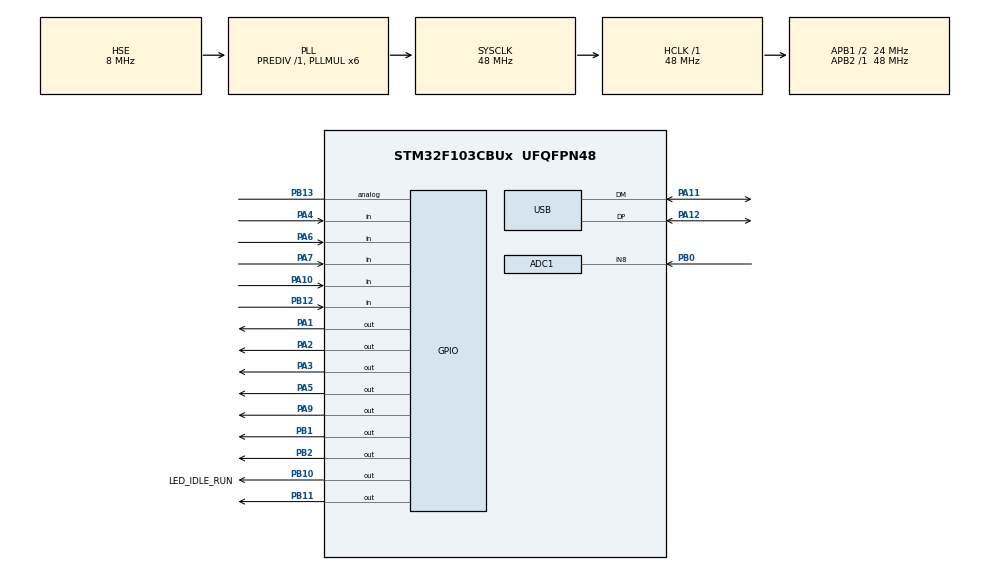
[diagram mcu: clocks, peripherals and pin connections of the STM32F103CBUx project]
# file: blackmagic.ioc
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ADC1.Channel-0\#ChannelRegularConversion=ADC_CHANNEL_8
ADC1.NbrOfConversionFlag=1
ADC1.Rank-0\#ChannelRegularConversion=1
ADC1.SamplingTime-0\#ChannelRegularConversion=ADC_SAMPLETIME_1CYCLE_5
ADC1.master=1
Mcu.Family=STM32F1
Mcu.Name=STM32F103CBUx
Mcu.Package=UFQFPN48
NVIC.PriorityGroup=NVIC_PRIORITYGROUP_4
NVIC.USB_LP_CAN1_RX0_IRQn=true\:0\:0\:false\:false\:true\:false\:true
PA1.Signal=GPIO_Output
PA10.Signal=GPIO_Input
PA11.Mode=Device
PA11.Signal=USB_DM
PA12.Mode=Device
PA12.Signal=USB_DP
PA13.Mode=Serial_Wire
PA13.Signal=SYS_JTMS-SWDIO
PA14.Mode=Serial_Wire
PA14.Signal=SYS_JTCK-SWCLK
PA2.Signal=GPIO_Output
PA3.Signal=GPIO_Output
PA4.Signal=GPIO_Input
PA5.Signal=GPIO_Output
PA6.Signal=GPIO_Input
PA7.Signal=GPIO_Input
PA9.Signal=GPIO_Output
PB0.Signal=ADCx_IN8
PB1.Signal=GPIO_Output
PB10.GPIO_Label=LED_IDLE_RUN
PB10.Signal=GPIO_Output
PB11.Signal=GPIO_Output
PB12.Signal=GPIO_Input
PB13.Signal=GPIO_Analog
PB2.Signal=GPIO_Output
PB3.Signal=SYS_JTDO-TRACESWO
PD0-OSC_IN.Mode=HSE-External-Oscillator
PD0-OSC_IN.Signal=RCC_OSC_IN
PD1-OSC_OUT.Mode=HSE-External-Oscillator
PD1-OSC_OUT.Signal=RCC_OSC_OUT
ProjectManager.HeapSize=0x200
ProjectManager.StackSize=0x400
ProjectManager.TargetToolchain=STM32CubeIDE
RCC.ADCPresc=RCC_ADCPCLK2_DIV4
RCC.AHBFreq_Value=48000000
RCC.APB1CLKDivider=RCC_HCLK_DIV2
RCC.APB1Freq_Value=24000000
RCC.APB1TimFreq_Value=48000000
RCC.APB2Freq_Value=48000000
RCC.APB2TimFreq_Value=48000000
RCC.HCLKFreq_Value=48000000
RCC.PLLMUL=RCC_PLL_MUL6
RCC.SYSCLKFreq_VALUE=48000000
RCC.SYSCLKSource=RCC_SYSCLKSOURCE_PLLCLK
RCC.USBFreq_Value=48000000
SH.ADCx_IN8.0=ADC1_IN8,IN8
USB_DEVICE.CLASS_NAME_FS=CDC
USB_DEVICE.VirtualMode=Cdc
USB_DEVICE.VirtualModeFS=Cdc_FS
VP_USB_DEVICE_VS_USB_DEVICE_CDC_FS.Mode=CDC_FS
board=custom

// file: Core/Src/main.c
/* USER CODE BEGIN Header */
/**
  ******************************************************************************
  * @file           : main.c
  * @brief          : Main program body
  ******************************************************************************
  * @attention
  *
  * <h2><center>&copy; Copyright (c) 2020 STMicroelectronics.
  * All rights reserved.</center></h2>
  *
  * This software component is licensed by ST under BSD 3-Clause license,
  * the "License"; You may not use this file except in compliance with the
  * License. You may obtain a copy of the License at:
  *                        opensource.org/licenses/BSD-3-Clause
  *
  ******************************************************************************
  */
/* USER CODE END Header */

#include "main.h"
#include "usb_device.h"

/* USER CODE BEGIN Includes */
#include "exception.h"

/* USER CODE END Includes */

ADC_HandleTypeDef hadc1;

/* USER CODE BEGIN PV */
uint8_t running_status;
/* USER CODE END PV */

void SystemClock_Config(void);
static void MX_GPIO_Init(void);
static void MX_ADC1_Init(void);

int main(void)
{

  /* MCU Configuration--------------------------------------------------------*/

  /* Reset of all peripherals, Initializes the Flash interface and the Systick. */
  HAL_Init();

  /* Configure the system clock */
  SystemClock_Config();

  /* Initialize all configured peripherals */
  MX_GPIO_Init();
  MX_ADC1_Init();
  MX_USB_DEVICE_Init();

  /* Infinite loop */
  while (1)
  {
	  volatile struct exception e;
	  TRY_CATCH(e, EXCEPTION_ALL)
	  {
		  gdb_main();
	  }
	  if (e.type)
	  {
//		  gdb_putpacketz("EFF");
//		  target_list_free();
//		  morse("TARGET LOST.", 1);
	  }
  }
}

void SystemClock_Config(void)
{
  RCC_OscInitTypeDef RCC_OscInitStruct = {0};
  RCC_ClkInitTypeDef RCC_ClkInitStruct = {0};
  RCC_PeriphCLKInitTypeDef PeriphClkInit = {0};

  /** Initializes the CPU, AHB and APB busses clocks
  */
  RCC_OscInitStruct.OscillatorType = RCC_OSCILLATORTYPE_HSE;
  RCC_OscInitStruct.HSEState = RCC_HSE_ON;
  RCC_OscInitStruct.HSEPredivValue = RCC_HSE_PREDIV_DIV1;
  RCC_OscInitStruct.HSIState = RCC_HSI_ON;
  RCC_OscInitStruct.PLL.PLLState = RCC_PLL_ON;
  RCC_OscInitStruct.PLL.PLLSource = RCC_PLLSOURCE_HSE;
  RCC_OscInitStruct.PLL.PLLMUL = RCC_PLL_MUL6;
  if (HAL_RCC_OscConfig(&RCC_OscInitStruct) != HAL_OK)
  {
    Error_Handler();
  }
  /** Initializes the CPU, AHB and APB busses clocks
  */
  RCC_ClkInitStruct.ClockType = RCC_CLOCKTYPE_HCLK|RCC_CLOCKTYPE_SYSCLK
                              |RCC_CLOCKTYPE_PCLK1|RCC_CLOCKTYPE_PCLK2;
  RCC_ClkInitStruct.SYSCLKSource = RCC_SYSCLKSOURCE_PLLCLK;
  RCC_ClkInitStruct.AHBCLKDivider = RCC_SYSCLK_DIV1;
  RCC_ClkInitStruct.APB1CLKDivider = RCC_HCLK_DIV2;
  RCC_ClkInitStruct.APB2CLKDivider = RCC_HCLK_DIV1;

  if (HAL_RCC_ClockConfig(&RCC_ClkInitStruct, FLASH_LATENCY_1) != HAL_OK)
  {
    Error_Handler();
  }
  PeriphClkInit.PeriphClockSelection = RCC_PERIPHCLK_ADC|RCC_PERIPHCLK_USB;
  PeriphClkInit.AdcClockSelection = RCC_ADCPCLK2_DIV4;
  PeriphClkInit.UsbClockSelection = RCC_USBCLKSOURCE_PLL;
  if (HAL_RCCEx_PeriphCLKConfig(&PeriphClkInit) != HAL_OK)
  {
    Error_Handler();
  }
}

static void MX_ADC1_Init(void)
{

  ADC_ChannelConfTypeDef sConfig = {0};

  /** Common config
  */
  hadc1.Instance = ADC1;
  hadc1.Init.ScanConvMode = ADC_SCAN_DISABLE;
  hadc1.Init.ContinuousConvMode = DISABLE;
  hadc1.Init.DiscontinuousConvMode = DISABLE;
  hadc1.Init.ExternalTrigConv = ADC_SOFTWARE_START;
  hadc1.Init.DataAlign = ADC_DATAALIGN_RIGHT;
  hadc1.Init.NbrOfConversion = 1;
  if (HAL_ADC_Init(&hadc1) != HAL_OK)
  {
    Error_Handler();
  }
  /** Configure Regular Channel
  */
  sConfig.Channel = ADC_CHANNEL_8;
  sConfig.Rank = ADC_REGULAR_RANK_1;
  sConfig.SamplingTime = ADC_SAMPLETIME_1CYCLE_5;
  if (HAL_ADC_ConfigChannel(&hadc1, &sConfig) != HAL_OK)
  {
    Error_Handler();
  }

}

static void MX_GPIO_Init(void)
{
  GPIO_InitTypeDef GPIO_InitStruct = {0};

  /* GPIO Ports Clock Enable */
  __HAL_RCC_GPIOD_CLK_ENABLE();
  __HAL_RCC_GPIOA_CLK_ENABLE();
  __HAL_RCC_GPIOB_CLK_ENABLE();

  /*Configure GPIO pin Output Level */
  HAL_GPIO_WritePin(GPIOA, GPIO_PIN_1|GPIO_PIN_2|GPIO_PIN_3|GPIO_PIN_5
                          |GPIO_PIN_9, GPIO_PIN_RESET);

  /*Configure GPIO pin Output Level */
  HAL_GPIO_WritePin(GPIOB, GPIO_PIN_1|GPIO_PIN_2|LED_IDLE_RUN_Pin|GPIO_PIN_11, GPIO_PIN_RESET);

  /*Configure GPIO pins : PA1 PA2 PA3 PA5
                           PA9 */
  GPIO_InitStruct.Pin = GPIO_PIN_1|GPIO_PIN_2|GPIO_PIN_3|GPIO_PIN_5
                          |GPIO_PIN_9;
  GPIO_InitStruct.Mode = GPIO_MODE_OUTPUT_PP;
  GPIO_InitStruct.Pull = GPIO_NOPULL;
  GPIO_InitStruct.Speed = GPIO_SPEED_FREQ_LOW;
  HAL_GPIO_Init(GPIOA, &GPIO_InitStruct);

  /*Configure GPIO pins : PA4 PA6 PA7 PA10 */
  GPIO_InitStruct.Pin = GPIO_PIN_4|GPIO_PIN_6|GPIO_PIN_7|GPIO_PIN_10;
  GPIO_InitStruct.Mode = GPIO_MODE_INPUT;
  GPIO_InitStruct.Pull = GPIO_NOPULL;
  HAL_GPIO_Init(GPIOA, &GPIO_InitStruct);

  /*Configure GPIO pins : PB1 PB2 LED_IDLE_RUN_Pin PB11 */
  GPIO_InitStruct.Pin = GPIO_PIN_1|GPIO_PIN_2|LED_IDLE_RUN_Pin|GPIO_PIN_11;
  GPIO_InitStruct.Mode = GPIO_MODE_OUTPUT_PP;
  GPIO_InitStruct.Pull = GPIO_NOPULL;
  GPIO_InitStruct.Speed = GPIO_SPEED_FREQ_LOW;
  HAL_GPIO_Init(GPIOB, &GPIO_InitStruct);

  /*Configure GPIO pin : PB12 */
  GPIO_InitStruct.Pin = GPIO_PIN_12;
  GPIO_InitStruct.Mode = GPIO_MODE_INPUT;
  GPIO_InitStruct.Pull = GPIO_NOPULL;
  HAL_GPIO_Init(GPIOB, &GPIO_InitStruct);

  /*Configure GPIO pin : PB13 */
  GPIO_InitStruct.Pin = GPIO_PIN_13;
  GPIO_InitStruct.Mode = GPIO_MODE_ANALOG;
  HAL_GPIO_Init(GPIOB, &GPIO_InitStruct);

}

void Error_Handler(void)
{
}

/************************ (C) COPYRIGHT STMicroelectronics *****END OF FILE****/
